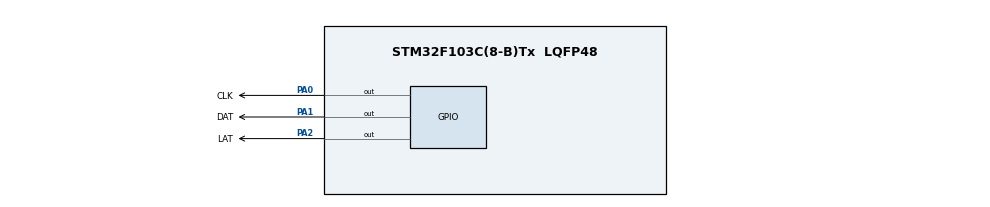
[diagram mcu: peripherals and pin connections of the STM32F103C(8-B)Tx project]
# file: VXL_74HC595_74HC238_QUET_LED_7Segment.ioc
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Mcu.Family=STM32F1
Mcu.Name=STM32F103C(8-B)Tx
Mcu.Package=LQFP48
NVIC.PriorityGroup=NVIC_PRIORITYGROUP_4
PA0-WKUP.GPIO_Label=CLK
PA0-WKUP.Signal=GPIO_Output
PA1.GPIO_Label=DAT
PA1.Signal=GPIO_Output
PA13.Mode=Serial_Wire
PA13.Signal=SYS_JTMS-SWDIO
PA14.Mode=Serial_Wire
PA14.Signal=SYS_JTCK-SWCLK
PA2.GPIO_Label=LAT
PA2.Signal=GPIO_Output
ProjectManager.HeapSize=0x200
ProjectManager.StackSize=0x400
ProjectManager.TargetToolchain=MDK-ARM V5.32
RCC.APB1Freq_Value=8000000
RCC.APB2Freq_Value=8000000
board=custom

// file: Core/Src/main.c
/* USER CODE BEGIN Header */
/**
  ******************************************************************************
  * @file           : main.c
  * @brief          : Main program body
  ******************************************************************************
  * @attention
  *
  * Copyright (c) 2023 STMicroelectronics.
  * All rights reserved.
  *
  * This software is licensed under terms that can be found in the LICENSE file
  * in the root directory of this software component.
  * If no LICENSE file comes with this software, it is provided AS-IS.
  *
  ******************************************************************************
  */
/* USER CODE END Header */
#include "main.h"

/* USER CODE BEGIN PV */
const uint8_t LED[] = {0x03,0x9F,0x25,0x0D,0x99,0x49,0x41,0x1F,0x01,0x09};
uint32_t count = 31200 ; // set h ban dau
uint8_t sec_donvi;
uint8_t sec_chuc;
uint8_t min_donvi;
uint8_t min_chuc;
uint8_t hour_donvi;
uint8_t hour_chuc;
/* USER CODE END PV */

void SystemClock_Config(void);
static void MX_GPIO_Init(void);

/* USER CODE BEGIN 0 */
void CLK(uint32_t n){
	while(n>0){
		HAL_GPIO_WritePin(CLK_GPIO_Port,CLK_Pin,1);
		HAL_GPIO_WritePin(CLK_GPIO_Port,CLK_Pin,0);
		n = n-1;
	}
}

void set_LED(uint8_t pos, uint8_t NUM, uint8_t dot){
	HAL_GPIO_WritePin(DAT_GPIO_Port,DAT_Pin,(pos+1)>>2&1u);
	CLK(1);
	HAL_GPIO_WritePin(DAT_GPIO_Port,DAT_Pin,(pos+1)>>1&1u);
	CLK(1);
	HAL_GPIO_WritePin(DAT_GPIO_Port,DAT_Pin,(pos+1)&1u);
	CLK(1);

	for(int8_t k = 0; k <8;k++){
		HAL_GPIO_WritePin(DAT_GPIO_Port,DAT_Pin,((LED[NUM]&(254 + dot))>>k&1u)); // 254 bien bit cuoi thanh 0 -> dau cham. 255 thi khong co dau cham
		CLK(1);
	}

	HAL_GPIO_WritePin(LAT_GPIO_Port,LAT_Pin,1);
	HAL_GPIO_WritePin(LAT_GPIO_Port,LAT_Pin,0);

	HAL_Delay(1);
	// chong lem
	for(int8_t k = 0; k <8;k++){
		HAL_GPIO_WritePin(DAT_GPIO_Port,DAT_Pin,1); // off all. chong lem
		CLK(1);
	}
	HAL_GPIO_WritePin(LAT_GPIO_Port,LAT_Pin,1);
	HAL_GPIO_WritePin(LAT_GPIO_Port,LAT_Pin,0);

}

/* USER CODE END 0 */

int main(void)
{

  /* MCU Configuration--------------------------------------------------------*/

  /* Reset of all peripherals, Initializes the Flash interface and the Systick. */
  HAL_Init();

  /* Configure the system clock */
  SystemClock_Config();

  /* Initialize all configured peripherals */
  MX_GPIO_Init();

  /* Infinite loop */
  while (1)
  {
		if (count > 86399) count = 0;
		hour_chuc = (count/3600)/10;
		hour_donvi = (count/3600)%10;
		min_chuc = ((count/60)/10)%6; // <6
		min_donvi = (count/60)%10;
		sec_chuc = (count/10)%6;
		sec_donvi = count%10;

		uint32_t w = 167;
		while (w>0) {
			set_LED(1,hour_chuc,1);
			set_LED(2,hour_donvi,0);
			set_LED(3,min_chuc,1);
			set_LED(4,min_donvi,0);
			set_LED(5,sec_chuc,1);
			set_LED(6,sec_donvi,1);
			w = w -1;
		}
		count = count+1;
  }
}

void SystemClock_Config(void)
{
  RCC_OscInitTypeDef RCC_OscInitStruct = {0};
  RCC_ClkInitTypeDef RCC_ClkInitStruct = {0};

  /** Initializes the RCC Oscillators according to the specified parameters
  * in the RCC_OscInitTypeDef structure.
  */
  RCC_OscInitStruct.OscillatorType = RCC_OSCILLATORTYPE_HSI;
  RCC_OscInitStruct.HSIState = RCC_HSI_ON;
  RCC_OscInitStruct.HSICalibrationValue = RCC_HSICALIBRATION_DEFAULT;
  RCC_OscInitStruct.PLL.PLLState = RCC_PLL_NONE;
  if (HAL_RCC_OscConfig(&RCC_OscInitStruct) != HAL_OK)
  {
    Error_Handler();
  }

  /** Initializes the CPU, AHB and APB buses clocks
  */
  RCC_ClkInitStruct.ClockType = RCC_CLOCKTYPE_HCLK|RCC_CLOCKTYPE_SYSCLK
                              |RCC_CLOCKTYPE_PCLK1|RCC_CLOCKTYPE_PCLK2;
  RCC_ClkInitStruct.SYSCLKSource = RCC_SYSCLKSOURCE_HSI;
  RCC_ClkInitStruct.AHBCLKDivider = RCC_SYSCLK_DIV1;
  RCC_ClkInitStruct.APB1CLKDivider = RCC_HCLK_DIV1;
  RCC_ClkInitStruct.APB2CLKDivider = RCC_HCLK_DIV1;

  if (HAL_RCC_ClockConfig(&RCC_ClkInitStruct, FLASH_LATENCY_0) != HAL_OK)
  {
    Error_Handler();
  }
}

static void MX_GPIO_Init(void)
{
  GPIO_InitTypeDef GPIO_InitStruct = {0};

  /* GPIO Ports Clock Enable */
  __HAL_RCC_GPIOC_CLK_ENABLE();
  __HAL_RCC_GPIOD_CLK_ENABLE();
  __HAL_RCC_GPIOA_CLK_ENABLE();
  __HAL_RCC_GPIOB_CLK_ENABLE();

  /*Configure GPIO pin Output Level */
  HAL_GPIO_WritePin(GPIOA, CLK_Pin|DAT_Pin|LAT_Pin, GPIO_PIN_RESET);

  /*Configure GPIO pins : PC13 PC14 PC15 */
  GPIO_InitStruct.Pin = GPIO_PIN_13|GPIO_PIN_14|GPIO_PIN_15;
  GPIO_InitStruct.Mode = GPIO_MODE_ANALOG;
  HAL_GPIO_Init(GPIOC, &GPIO_InitStruct);

  /*Configure GPIO pins : PD0 PD1 */
  GPIO_InitStruct.Pin = GPIO_PIN_0|GPIO_PIN_1;
  GPIO_InitStruct.Mode = GPIO_MODE_ANALOG;
  HAL_GPIO_Init(GPIOD, &GPIO_InitStruct);

  /*Configure GPIO pins : CLK_Pin DAT_Pin LAT_Pin */
  GPIO_InitStruct.Pin = CLK_Pin|DAT_Pin|LAT_Pin;
  GPIO_InitStruct.Mode = GPIO_MODE_OUTPUT_PP;
  GPIO_InitStruct.Pull = GPIO_NOPULL;
  GPIO_InitStruct.Speed = GPIO_SPEED_FREQ_LOW;
  HAL_GPIO_Init(GPIOA, &GPIO_InitStruct);

  /*Configure GPIO pins : PA3 PA4 PA5 PA6
                           PA7 PA8 PA9 PA10
                           PA11 PA12 PA15 */
  GPIO_InitStruct.Pin = GPIO_PIN_3|GPIO_PIN_4|GPIO_PIN_5|GPIO_PIN_6
                          |GPIO_PIN_7|GPIO_PIN_8|GPIO_PIN_9|GPIO_PIN_10
                          |GPIO_PIN_11|GPIO_PIN_12|GPIO_PIN_15;
  GPIO_InitStruct.Mode = GPIO_MODE_ANALOG;
  HAL_GPIO_Init(GPIOA, &GPIO_InitStruct);

  /*Configure GPIO pins : PB0 PB1 PB2 PB10
                           PB11 PB12 PB13 PB14
                           PB15 PB3 PB4 PB5
                           PB6 PB7 PB8 PB9 */
  GPIO_InitStruct.Pin = GPIO_PIN_0|GPIO_PIN_1|GPIO_PIN_2|GPIO_PIN_10
                          |GPIO_PIN_11|GPIO_PIN_12|GPIO_PIN_13|GPIO_PIN_14
                          |GPIO_PIN_15|GPIO_PIN_3|GPIO_PIN_4|GPIO_PIN_5
                          |GPIO_PIN_6|GPIO_PIN_7|GPIO_PIN_8|GPIO_PIN_9;
  GPIO_InitStruct.Mode = GPIO_MODE_ANALOG;
  HAL_GPIO_Init(GPIOB, &GPIO_InitStruct);

  /*Configure peripheral I/O remapping */
  __HAL_AFIO_REMAP_PD01_ENABLE();

}

void Error_Handler(void)
{
  __disable_irq();
  while (1)
  {
  }
}
